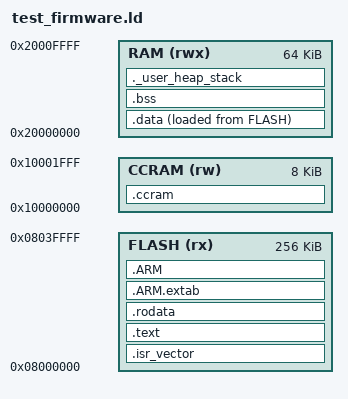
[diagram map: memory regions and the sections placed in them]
/* Test linker script for ARM Cortex-M */

/* Memory regions - typical embedded system layout */
MEMORY
{
    FLASH (rx)  : ORIGIN = 0x08000000, LENGTH = 256K
    RAM (rwx)   : ORIGIN = 0x20000000, LENGTH = 64K
    CCRAM (rw)  : ORIGIN = 0x10000000, LENGTH = 8K
}

/* Stack and heap sizes */
_Min_Heap_Size = 0x1000;  /* 4KB */
_Min_Stack_Size = 0x800;  /* 2KB */

/* Entry point */
ENTRY(reset_handler)

/* Sections */
SECTIONS
{
    /* Vector table goes to flash */
    .isr_vector :
    {
        . = ALIGN(4);
        KEEP(*(.isr_vector))
        . = ALIGN(4);
    } >FLASH

    /* Program code goes to flash */
    .text :
    {
        . = ALIGN(4);
        *(.text)
        *(.text*)
        *(.glue_7)
        *(.glue_7t)
        *(.eh_frame)
        
        KEEP (*(.init))
        KEEP (*(.fini))
        
        . = ALIGN(4);
        _etext = .;
    } >FLASH

    /* Constant data goes to flash */
    .rodata :
    {
        . = ALIGN(4);
        *(.rodata)
        *(.rodata*)
        . = ALIGN(4);
    } >FLASH

    /* ARM exception unwinding */
    .ARM.extab :
    {
        *(.ARM.extab* .gnu.linkonce.armextab.*)
    } >FLASH
    
    .ARM :
    {
        __exidx_start = .;
        *(.ARM.exidx*)
        __exidx_end = .;
    } >FLASH

    /* Initialized data - stored in flash, copied to RAM */
    .data : 
    {
        . = ALIGN(4);
        _sdata = .;
        *(.data)
        *(.data*)
        . = ALIGN(4);
        _edata = .;
    } >RAM AT> FLASH

    _sidata = LOADADDR(.data);

    /* Uninitialized data in RAM */
    .bss :
    {
        . = ALIGN(4);
        _sbss = .;
        __bss_start__ = _sbss;
        *(.bss)
        *(.bss*)
        *(COMMON)
        . = ALIGN(4);
        _ebss = .;
        __bss_end__ = _ebss;
    } >RAM

    /* User heap and stack */
    ._user_heap_stack :
    {
        . = ALIGN(8);
        PROVIDE ( end = . );
        PROVIDE ( _end = . );
        . = . + _Min_Heap_Size;
        . = . + _Min_Stack_Size;
        . = ALIGN(8);
        _estack = .;
    } >RAM

    /* CCRAM section for fast access data */
    .ccram :
    {
        . = ALIGN(4);
        _sccram = .;
        *(.ccram)
        *(.ccram*)
        . = ALIGN(4);
        _eccram = .;
    } >CCRAM

    /* Debug sections */
    .debug_info     0 : { *(.debug_info .gnu.linkonce.wi.*) }
    .debug_abbrev   0 : { *(.debug_abbrev) }
    .debug_line     0 : { *(.debug_line) }
    .debug_frame    0 : { *(.debug_frame) }
    .debug_str      0 : { *(.debug_str) }
    .debug_loc      0 : { *(.debug_loc) }
    .debug_macinfo  0 : { *(.debug_macinfo) }
    .debug_ranges   0 : { *(.debug_ranges) }
}

/* Symbols for runtime use */
_flash_size = LENGTH(FLASH);
_ram_size = LENGTH(RAM);
_ccram_size = LENGTH(CCRAM);

_flash_start = ORIGIN(FLASH);
_ram_start = ORIGIN(RAM);
_ccram_start = ORIGIN(CCRAM);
